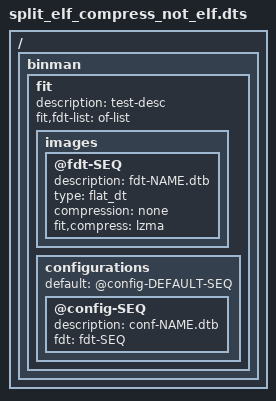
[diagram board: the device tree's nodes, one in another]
// SPDX-License-Identifier: GPL-2.0+

/dts-v1/;

/ {
	#address-cells = <1>;
	#size-cells = <1>;

	binman {
		fit {
			description = "test-desc";
			#address-cells = <1>;
			fit,fdt-list = "of-list";

			images {
				@fdt-SEQ {
					description = "fdt-NAME.dtb";
					type = "flat_dt";
					compression = "none";
					fit,compress = "lzma";
				};
			};

			configurations {
				default = "@config-DEFAULT-SEQ";
				@config-SEQ {
					description = "conf-NAME.dtb";
					fdt = "fdt-SEQ";
				};
			};
		};
	};
};
